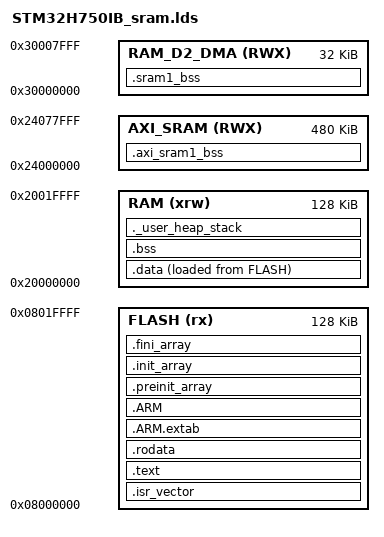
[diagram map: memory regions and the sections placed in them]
ENTRY(Reset_Handler)

_estack = 0x20000000 + 128K;
_Min_Heap_Size = 0x200;
_Min_Stack_Size = 0x400;

MEMORY
{
    FLASH (rx)      : ORIGIN = 0x8000000, LENGTH = 128K
    RAM (xrw)      : ORIGIN = 0x20000000, LENGTH = 128K
	AXI_SRAM  (RWX) : ORIGIN = 0x24000000, LENGTH = 512K - 32K
	RAM_D2_DMA  (RWX) : ORIGIN = 0x30000000, LENGTH = 32K
}

SECTIONS
{
  .isr_vector :
  {
    . = ALIGN(4);
    KEEP(*(.isr_vector))
    . = ALIGN(4);
  } >FLASH

  .text :
  {
    . = ALIGN(4);
    *(.text)
    *(.text*)
    *(.glue_7)
    *(.glue_7t)
    *(.eh_frame)

    KEEP (*(.init))
    KEEP (*(.fini))

    . = ALIGN(4);
    _etext = .;
  } >FLASH

  .rodata :
  {
    . = ALIGN(4);
    *(.rodata)
    *(.rodata*)
    . = ALIGN(4);
  } >FLASH

  .ARM.extab   : { *(.ARM.extab* .gnu.linkonce.armextab.*) } >FLASH
  .ARM : {
    __exidx_start = .;
    *(.ARM.exidx*)
    __exidx_end = .;
  } >FLASH

  .preinit_array     :
  {
    PROVIDE_HIDDEN (__preinit_array_start = .);
    KEEP (*(.preinit_array*))
    PROVIDE_HIDDEN (__preinit_array_end = .);
  } >FLASH
  .init_array :
  {
    PROVIDE_HIDDEN (__init_array_start = .);
    KEEP (*(SORT(.init_array.*)))
    KEEP (*(.init_array*))
    PROVIDE_HIDDEN (__init_array_end = .);
  } >FLASH
  .fini_array :
  {
    PROVIDE_HIDDEN (__fini_array_start = .);
    KEEP (*(SORT(.fini_array.*)))
    KEEP (*(.fini_array*))
    PROVIDE_HIDDEN (__fini_array_end = .);
  } >FLASH

  _sidata = LOADADDR(.data);

  .data : 
  {
    . = ALIGN(4);
    _sdata = .; 
    *(.data)
    *(.data*)

    . = ALIGN(4);
    _edata = .;
  } >RAM AT> FLASH

  . = ALIGN(4);
  .bss :
  {
    _sbss = .;
    __bss_start__ = _sbss;
    *(.bss)
    *(.bss*)
    *(COMMON)

    . = ALIGN(4);
    _ebss = .;
    __bss_end__ = _ebss;
  } >RAM

  ._user_heap_stack :
  {
    . = ALIGN(8);
    PROVIDE ( end = . );
    PROVIDE ( _end = . );
    . = . + _Min_Heap_Size;
    . = . + _Min_Stack_Size;
    . = ALIGN(8);
  } >RAM

  /DISCARD/ :
  {
    libc.a ( * )
    libm.a ( * )
    libgcc.a ( * )
  }

    .axi_sram1_bss (NOLOAD) :
	{
		. = ALIGN(4);
		_saxi_sram1_bss = .;

		PROVIDE(__axi_sram1_bss_start__ = _axi_sram1_bss);
		*(.axi_sram1_bss)
		*(.axi_sram1_bss*)
		. = ALIGN(4);
		_esram1_bss = .;

		PROVIDE(__axi_sram1_bss_end__ = _eaxi_sram1_bss);
	} > AXI_SRAM

	.sram1_bss (NOLOAD) :
	{
		. = ALIGN(4);
		_ssram1_bss = .;

		PROVIDE(__sram1_bss_start__ = _sram1_bss);
		*(.sram1_bss)
		*(.sram1_bss*)
		. = ALIGN(4);
		_esram1_bss = .;

		PROVIDE(__sram1_bss_end__ = _esram1_bss);
	} > RAM_D2_DMA

  .ARM.attributes 0 : { *(.ARM.attributes) }

}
